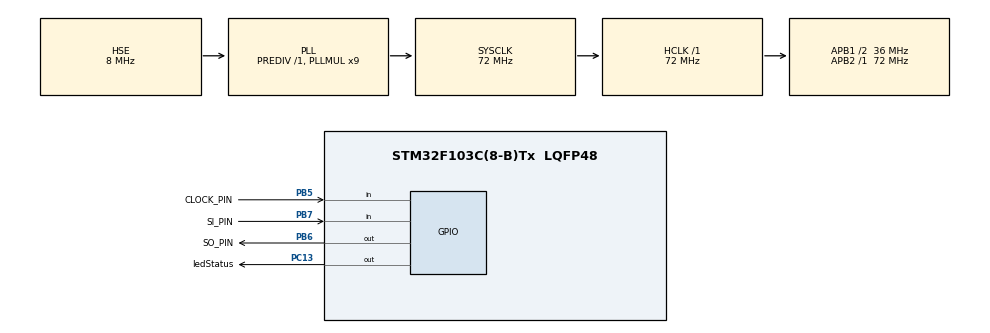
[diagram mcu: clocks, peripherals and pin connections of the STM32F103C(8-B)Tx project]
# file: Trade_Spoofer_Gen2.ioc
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Mcu.Family=STM32F1
Mcu.Name=STM32F103C(8-B)Tx
Mcu.Package=LQFP48
NVIC.EXTI9_5_IRQn=true\:0\:0\:false\:false\:true\:true\:true\:true
NVIC.PriorityGroup=NVIC_PRIORITYGROUP_4
NVIC.TIM2_IRQn=true\:0\:0\:false\:false\:true\:true\:true\:true
PA13.Mode=Serial_Wire
PA13.Signal=SYS_JTMS-SWDIO
PA14.Mode=Serial_Wire
PA14.Signal=SYS_JTCK-SWCLK
PB5.GPIO_Label=CLOCK_PIN
PB5.GPIO_PuPd=GPIO_PULLUP
PB5.Signal=SharedStack_PB5
PB5.Stacked=true
PB6.GPIO_Label=SO_PIN
PB6.Signal=GPIO_Output
PB7.GPIO_Label=SI_PIN
PB7.GPIO_PuPd=GPIO_PULLUP
PB7.Signal=GPIO_Input
PC13-TAMPER-RTC.GPIO_Label=ledStatus
PC13-TAMPER-RTC.Signal=GPIO_Output
PD0-OSC_IN.Mode=HSE-External-Oscillator
PD0-OSC_IN.Signal=RCC_OSC_IN
PD1-OSC_OUT.Mode=HSE-External-Oscillator
PD1-OSC_OUT.Signal=RCC_OSC_OUT
ProjectManager.HeapSize=0x200
ProjectManager.StackSize=0x400
ProjectManager.TargetToolchain=STM32CubeIDE
RCC.AHBFreq_Value=72000000
RCC.APB1CLKDivider=RCC_HCLK_DIV2
RCC.APB1Freq_Value=36000000
RCC.APB1TimFreq_Value=72000000
RCC.APB2Freq_Value=72000000
RCC.APB2TimFreq_Value=72000000
RCC.HCLKFreq_Value=72000000
RCC.PLLMUL=RCC_PLL_MUL9
RCC.PLLSourceVirtual=RCC_PLLSOURCE_HSE
RCC.SYSCLKFreq_VALUE=72000000
RCC.SYSCLKSource=RCC_SYSCLKSOURCE_PLLCLK
RCC.USBFreq_Value=72000000
SH.SharedStack_PB5.0=GPIO_Input+0
SH.SharedStack_PB5.1=GPIO_EXTI5
TIM2.Period=72
VP_TIM2_VS_ClockSourceINT.Mode=Internal
board=custom

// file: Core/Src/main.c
/* USER CODE BEGIN Header */
/**
  ******************************************************************************
  * @file           : main.c
  * @brief          : Main program body
  ******************************************************************************
  * @attention
  *
  * Copyright (c) 2022 STMicroelectronics.
  * All rights reserved.
  *
  * This software is licensed under terms that can be found in the LICENSE file
  * in the root directory of this software component.
  * If no LICENSE file comes with this software, it is provided AS-IS.
  *
  ******************************************************************************
  */
/* USER CODE END Header */
#include "main.h"
#include "slave_gameboy_pde.h"

 TIM_HandleTypeDef htim2;

void SystemClock_Config(void);
static void MX_GPIO_Init(void);
static void MX_TIM2_Init(void);

int main(void)
{

  /* MCU Configuration--------------------------------------------------------*/

  /* Reset of all peripherals, Initializes the Flash interface and the Systick. */
  HAL_Init();

  /* Configure the system clock */
  SystemClock_Config();

  /* Initialize all configured peripherals */
  MX_GPIO_Init();
  MX_TIM2_Init();

  /* Infinite loop */
  while (1)
  {

  }
}

void SystemClock_Config(void)
{
  RCC_OscInitTypeDef RCC_OscInitStruct = {0};
  RCC_ClkInitTypeDef RCC_ClkInitStruct = {0};

  /** Initializes the RCC Oscillators according to the specified parameters
  * in the RCC_OscInitTypeDef structure.
  */
  RCC_OscInitStruct.OscillatorType = RCC_OSCILLATORTYPE_HSE;
  RCC_OscInitStruct.HSEState = RCC_HSE_ON;
  RCC_OscInitStruct.HSEPredivValue = RCC_HSE_PREDIV_DIV1;
  RCC_OscInitStruct.HSIState = RCC_HSI_ON;
  RCC_OscInitStruct.PLL.PLLState = RCC_PLL_ON;
  RCC_OscInitStruct.PLL.PLLSource = RCC_PLLSOURCE_HSE;
  RCC_OscInitStruct.PLL.PLLMUL = RCC_PLL_MUL9;
  if (HAL_RCC_OscConfig(&RCC_OscInitStruct) != HAL_OK)
  {
    Error_Handler();
  }

  /** Initializes the CPU, AHB and APB buses clocks
  */
  RCC_ClkInitStruct.ClockType = RCC_CLOCKTYPE_HCLK|RCC_CLOCKTYPE_SYSCLK
                              |RCC_CLOCKTYPE_PCLK1|RCC_CLOCKTYPE_PCLK2;
  RCC_ClkInitStruct.SYSCLKSource = RCC_SYSCLKSOURCE_PLLCLK;
  RCC_ClkInitStruct.AHBCLKDivider = RCC_SYSCLK_DIV1;
  RCC_ClkInitStruct.APB1CLKDivider = RCC_HCLK_DIV2;
  RCC_ClkInitStruct.APB2CLKDivider = RCC_HCLK_DIV1;

  if (HAL_RCC_ClockConfig(&RCC_ClkInitStruct, FLASH_LATENCY_2) != HAL_OK)
  {
    Error_Handler();
  }
}

static void MX_TIM2_Init(void)
{

  TIM_ClockConfigTypeDef sClockSourceConfig = {0};
  TIM_MasterConfigTypeDef sMasterConfig = {0};

  htim2.Instance = TIM2;
  htim2.Init.Prescaler = 0;
  htim2.Init.CounterMode = TIM_COUNTERMODE_UP;
  htim2.Init.Period = 72;
  htim2.Init.ClockDivision = TIM_CLOCKDIVISION_DIV1;
  htim2.Init.AutoReloadPreload = TIM_AUTORELOAD_PRELOAD_DISABLE;
  if (HAL_TIM_Base_Init(&htim2) != HAL_OK)
  {
    Error_Handler();
  }
  sClockSourceConfig.ClockSource = TIM_CLOCKSOURCE_INTERNAL;
  if (HAL_TIM_ConfigClockSource(&htim2, &sClockSourceConfig) != HAL_OK)
  {
    Error_Handler();
  }
  sMasterConfig.MasterOutputTrigger = TIM_TRGO_RESET;
  sMasterConfig.MasterSlaveMode = TIM_MASTERSLAVEMODE_DISABLE;
  if (HAL_TIMEx_MasterConfigSynchronization(&htim2, &sMasterConfig) != HAL_OK)
  {
    Error_Handler();
  }

}

static void MX_GPIO_Init(void)
{
  GPIO_InitTypeDef GPIO_InitStruct = {0};

  /* GPIO Ports Clock Enable */
  __HAL_RCC_GPIOC_CLK_ENABLE();
  __HAL_RCC_GPIOD_CLK_ENABLE();
  __HAL_RCC_GPIOA_CLK_ENABLE();
  __HAL_RCC_GPIOB_CLK_ENABLE();

  /*Configure GPIO pin Output Level */
  HAL_GPIO_WritePin(ledStatus_GPIO_Port, ledStatus_Pin, GPIO_PIN_RESET);

  /*Configure GPIO pin Output Level */
  HAL_GPIO_WritePin(SO_PIN_GPIO_Port, SO_PIN_Pin, GPIO_PIN_RESET);

  /*Configure GPIO pin : ledStatus_Pin */
  GPIO_InitStruct.Pin = ledStatus_Pin;
  GPIO_InitStruct.Mode = GPIO_MODE_OUTPUT_PP;
  GPIO_InitStruct.Pull = GPIO_NOPULL;
  GPIO_InitStruct.Speed = GPIO_SPEED_FREQ_LOW;
  HAL_GPIO_Init(ledStatus_GPIO_Port, &GPIO_InitStruct);

  /*Configure GPIO pin : CLOCK_PIN_Pin */
  GPIO_InitStruct.Pin = CLOCK_PIN_Pin;
  GPIO_InitStruct.Mode = GPIO_MODE_IT_RISING;
  GPIO_InitStruct.Pull = GPIO_PULLUP;
  HAL_GPIO_Init(CLOCK_PIN_GPIO_Port, &GPIO_InitStruct);

  /*Configure GPIO pin : SO_PIN_Pin */
  GPIO_InitStruct.Pin = SO_PIN_Pin;
  GPIO_InitStruct.Mode = GPIO_MODE_OUTPUT_PP;
  GPIO_InitStruct.Pull = GPIO_NOPULL;
  GPIO_InitStruct.Speed = GPIO_SPEED_FREQ_LOW;
  HAL_GPIO_Init(SO_PIN_GPIO_Port, &GPIO_InitStruct);

  /*Configure GPIO pin : SI_PIN_Pin */
  GPIO_InitStruct.Pin = SI_PIN_Pin;
  GPIO_InitStruct.Mode = GPIO_MODE_INPUT;
  GPIO_InitStruct.Pull = GPIO_PULLUP;
  HAL_GPIO_Init(SI_PIN_GPIO_Port, &GPIO_InitStruct);

  /* EXTI interrupt init*/
  HAL_NVIC_SetPriority(EXTI9_5_IRQn, 0, 0);
  HAL_NVIC_EnableIRQ(EXTI9_5_IRQn);

}

/* USER CODE BEGIN 4 */

void EXTI9_5_IRQHandler()
{
	if(EXTI->PR & EXTI_PR_PR5)
		{
			EXTI->PR |= EXTI_PR_PR5;
			clockInterrupt();
		}
	else
	{
		EXTI->PR = 0xFFFF;
	}
}

/* USER CODE END 4 */

void Error_Handler(void)
{
  __disable_irq();
  while (1)
  {
  }
}
